AUTOSAR XML (schema 4-0-3)
package /EthernetSimple_Generic/Services/BswM
  impl type ComMModeEnum: compu {0=COMM_NO_COMMUNICATION, 1=COMM_SILENT_COMMUNICATION, 2=COMM_FULL_COMMUNICATION}, implementation-data-type=uint8
  sender receiver interface ComMModeRequestInterface
    data requestedMode: type=ComMModeEnum
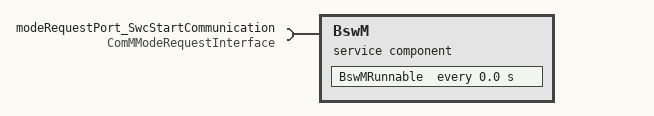
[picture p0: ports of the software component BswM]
  service sw component type BswM
    require port modeRequestPort_SwcStartCommunication: required-interface=ComMModeRequestInterface
    behavior BswMInternalBehavior: handle-termination-and-restart=NO-SUPPORT
      timing event BswMRunnableEvent: start-on-event=BswMRunnable, period=0.0
      runnable BswMRunnable: symbol=BswM_MainFunction
        data-receive-point-by-arguments:
          access dataReceivePoint_BswMRunnable_modeRequestPort_SwcStartCommunication_requestedMode: accessed-variable=modeRequestPort_SwcStartCommunication.requestedMode
  swc implementation BswMComponentImpl: programming-language=C, vendor-id=60, behavior=BswMInternalBehavior
    code-descriptors:
      code src: artifact-descriptors=autosar-engineering-object={short-label=artifactDescriptor, category=artifactDescriptorCategory}
    resource consumption resourceConsumption
package /EthernetSimple_Generic/Services/Os
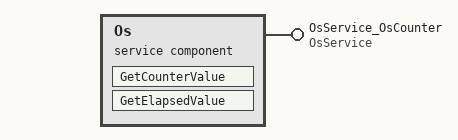
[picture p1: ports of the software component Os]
  service sw component type Os
    provide port OsService_OsCounter: provided-interface=OsService
    behavior OsBehavior: handle-termination-and-restart=NO-SUPPORT, port-api-option{port-defined-argument-value{value=CounterType:0, value-type=CounterType}, port=OsService_OsCounter}
      operation invoked event GetCounterValue_OsService_OsCounter_GetCounterValue: start-on-event=GetCounterValue, operation=OsService_OsCounter.GetCounterValue
      operation invoked event GetElapsedValue_OsService_OsCounter_GetElapsedValue: start-on-event=GetElapsedValue, operation=OsService_OsCounter.GetElapsedValue
      runnable GetCounterValue: symbol=Os_GetCounterValue
      runnable GetElapsedValue: symbol=Os_GetElapsedValue
  swc implementation OsImpl: programming-language=C, vendor-id=60, behavior=OsBehavior
    code-descriptors:
      code src: artifact-descriptors=autosar-engineering-object={short-label=artifactDescriptor, category=artifactDescriptorCategory}
    resource consumption resourceConsumption
package /EthernetSimple_Generic/Services/Det
  service sw component type Det
    behavior DetBehavior: handle-termination-and-restart=NO-SUPPORT
      runnable ReportError: symbol=Det_ReportError
  swc implementation DetImpl: programming-language=C, vendor-id=60, behavior=DetBehavior
    code-descriptors:
      code src: artifact-descriptors=autosar-engineering-object={short-label=artifactDescriptor, category=artifactDescriptorCategory}
    resource consumption resourceConsumption
package /EthernetSimple_Generic/Services/ComM
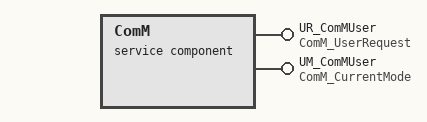
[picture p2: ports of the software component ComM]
  service sw component type ComM
    provide port UR_ComMUser: provided-interface=ComM_UserRequest
    provide port UM_ComMUser: provided-interface=ComM_CurrentMode
    behavior ComMBehavior: data-type-mapping=ComMTypeMappings, handle-termination-and-restart=NO-SUPPORT, port-api-option{port-defined-argument-value{value=ComM_UserHandleType:0, value-type=ComM_UserHandleType}, port=UR_ComMUser}
      4 x operation invoked event:
        RequestComMode_UR_ComMUser_RequestComMode: start-on-event=RequestComMode, operation=UR_ComMUser.RequestComMode
        GetMaxComMode_UR_ComMUser_GetMaxComMode: start-on-event=GetMaxComMode, operation=UR_ComMUser.GetMaxComMode
        GetRequestedComMode_UR_ComMUser_GetRequestedComMode: start-on-event=GetRequestedComMode, operation=UR_ComMUser.GetRequestedComMode
        GetCurrentComMode_UR_ComMUser_GetCurrentComMode: start-on-event=GetCurrentComMode, operation=UR_ComMUser.GetCurrentComMode
      5 x runnable:
        ComM_MainFunction
          mode switch point modeSwitchPoint_ComM_MainFunction_UM_ComMUser_currentMode: mode-group=UM_ComMUser.currentMode
        RequestComMode: can-be-invoked-concurrently=true, symbol=ComM_RequestComMode
        GetMaxComMode: can-be-invoked-concurrently=true, symbol=ComM_GetMaxComMode
        GetRequestedComMode: can-be-invoked-concurrently=true, symbol=ComM_GetRequestedComMode
        GetCurrentComMode: can-be-invoked-concurrently=true, symbol=ComM_GetCurrentComMode
  swc implementation ComMImpl: programming-language=C, vendor-id=60, behavior=ComMBehavior
    code-descriptors:
      code src: artifact-descriptors=autosar-engineering-object={short-label=artifactDescriptor, category=artifactDescriptorCategory}
    resource consumption resourceConsumption
package /EthernetSimple_Generic/Services/Dlt
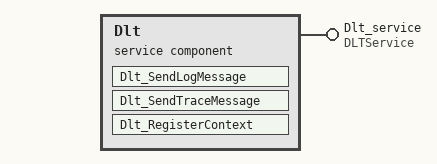
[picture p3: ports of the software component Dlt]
  service sw component type Dlt
    provide port Dlt_service: provided-interface=DLTService
    behavior DltBehavior: handle-termination-and-restart=NO-SUPPORT, port-api-option{port-defined-argument-value{value=Dlt_SessionIDType:4096, value-type=Dlt_SessionIDType}, port=Dlt_service}
      operation invoked event Dlt_SendLogMessage_Dlt_service_SendLogMessage: start-on-event=Dlt_SendLogMessage, operation=Dlt_service.SendLogMessage
      operation invoked event Dlt_SendTraceMessage_Dlt_service_SendTraceMessage: start-on-event=Dlt_SendTraceMessage, operation=Dlt_service.SendTraceMessage
      operation invoked event Dlt_RegisterContext_Dlt_service_RegisterContext: start-on-event=Dlt_RegisterContext, operation=Dlt_service.RegisterContext
      runnable Dlt_SendLogMessage
      runnable Dlt_SendTraceMessage
      runnable Dlt_RegisterContext
  swc implementation DltImpl: programming-language=C, vendor-id=60, behavior=DltBehavior
    code-descriptors:
      code src: artifact-descriptors=autosar-engineering-object={short-label=artifactDescriptor, category=artifactDescriptorCategory}
    resource consumption resourceConsumption
package /EthernetSimple_mpc5748g_mpc574xg_mb_Ecu/Services/EcuM
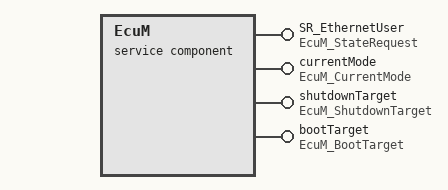
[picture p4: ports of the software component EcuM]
  service sw component type EcuM
    4 x provide port:
      SR_EthernetUser: provided-interface=EcuM_StateRequest
      currentMode: provided-interface=EcuM_CurrentMode
      shutdownTarget: provided-interface=EcuM_ShutdownTarget
      bootTarget: provided-interface=EcuM_BootTarget
    behavior EcuMFixedBehavior: data-type-mapping=EcuMFixedTypeMappings, handle-termination-and-restart=NO-SUPPORT, port-api-option{port-defined-argument-value{value=EcuM_UserType:0, value-type=EcuM_UserType}, port=SR_EthernetUser}
      9 x operation invoked event:
        RequestRUN_SR_EthernetUser_RequestRUN: start-on-event=RequestRUN, operation=SR_EthernetUser.RequestRUN
        ReleaseRUN_SR_EthernetUser_ReleaseRUN: start-on-event=ReleaseRUN, operation=SR_EthernetUser.ReleaseRUN
        RequestPOSTRUN_SR_EthernetUser_RequestPOSTRUN: start-on-event=RequestPOSTRUN, operation=SR_EthernetUser.RequestPOSTRUN
        ReleasePOSTRUN_SR_EthernetUser_ReleasePOSTRUN: start-on-event=ReleasePOSTRUN, operation=SR_EthernetUser.ReleasePOSTRUN
        SelectShutdownTarget_shutdownTarget_SelectShutdownTarget: start-on-event=SelectShutdownTarget, operation=shutdownTarget.SelectShutdownTarget
        GetShutdownTarget_shutdownTarget_GetShutdownTarget: start-on-event=GetShutdownTarget, operation=shutdownTarget.GetShutdownTarget
        GetLastShutdownTarget_shutdownTarget_GetLastShutdownTarget: start-on-event=GetLastShutdownTarget, operation=shutdownTarget.GetLastShutdownTarget
        SelectBootTarget_bootTarget_SelectBootTarget: start-on-event=SelectBootTarget, operation=bootTarget.SelectBootTarget
        GetBootTarget_bootTarget_GetBootTarget: start-on-event=GetBootTarget, operation=bootTarget.GetBootTarget
      10 x runnable:
        EcuM_MainFunction
          mode switch point modeSwitchPoint_EcuM_MainFunction_currentMode_currentMode: mode-group=currentMode.currentMode
        RequestRUN: can-be-invoked-concurrently=true, symbol=EcuM_RequestRUN
        ReleaseRUN: can-be-invoked-concurrently=true, symbol=EcuM_ReleaseRUN
        RequestPOSTRUN: can-be-invoked-concurrently=true, symbol=EcuM_RequestPOST_RUN
        ReleasePOSTRUN: can-be-invoked-concurrently=true, symbol=EcuM_ReleasePOST_RUN
        SelectShutdownTarget: can-be-invoked-concurrently=true, symbol=EcuM_SelectShutdownTarget
        GetShutdownTarget: can-be-invoked-concurrently=true, symbol=EcuM_GetShutdownTarget
        GetLastShutdownTarget: can-be-invoked-concurrently=true, symbol=EcuM_GetLastShutdownTarget
        SelectBootTarget: can-be-invoked-concurrently=true, symbol=EcuM_SelectBootTarget
        GetBootTarget: can-be-invoked-concurrently=true, symbol=EcuM_GetBootTarget
  swc implementation EcuMFixedImpl: programming-language=C, vendor-id=60, behavior=EcuMFixedBehavior
    code-descriptors:
      code src: artifact-descriptors=autosar-engineering-object={short-label=artifactDescriptor, category=artifactDescriptorCategory}
    resource consumption resourceConsumption
package /EthernetSimple_mpc5748g_mpc574xg_mb_Ecu/Services/IoHwAb
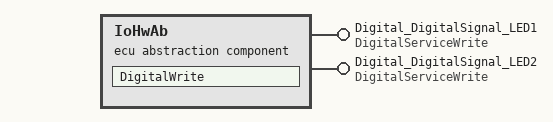
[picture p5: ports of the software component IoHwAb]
  ecu abstraction sw component type IoHwAb
    provide port Digital_DigitalSignal_LED1: provided-interface=DigitalServiceWrite
    provide port Digital_DigitalSignal_LED2: provided-interface=DigitalServiceWrite
    behavior IoHwAbBehavior: handle-termination-and-restart=NO-SUPPORT
      operation invoked event DigitalWrite_Digital_DigitalSignal_LED1_Write: start-on-event=DigitalWrite, operation=Digital_DigitalSignal_LED1.Write
      operation invoked event DigitalWrite_Digital_DigitalSignal_LED2_Write: start-on-event=DigitalWrite, operation=Digital_DigitalSignal_LED2.Write
      port-api-options:
        {port-defined-argument-value{value=IoHwAb_SignalType_:0, value-type=IoHwAb_SignalType_}, port=Digital_DigitalSignal_LED1}
        {port-defined-argument-value{value=IoHwAb_SignalType_:1, value-type=IoHwAb_SignalType_}, port=Digital_DigitalSignal_LED2}
      runnable DigitalWrite: can-be-invoked-concurrently=true, symbol=IoHwAb_Digital_Write
  swc implementation IoHwAbImpl: programming-language=C, vendor-id=60, behavior=IoHwAbBehavior
    code-descriptors:
      code src: artifact-descriptors=autosar-engineering-object={short-label=artifactDescriptor, category=artifactDescriptorCategory}
    resource consumption resourceConsumption
package /EthernetSimple
  system EthernetSimple: category=ECU_EXTRACT, system-version=1
    system mapping ImplementationMappings
      sw-impl-mappings:
        7 x swc to impl mapping:
          comMMapping: component-implementation=ComMImpl, component=RootSwComposition.comM
          dltMapping: component-implementation=DltImpl, component=RootSwComposition.dlt
          bswMMapping: component-implementation=BswMComponentImpl, component=RootSwComposition.bswm
          ecuMMapping: component-implementation=EcuMFixedImpl, component=RootSwComposition.ecuM
          ioHwAbMapping: component-implementation=IoHwAbImpl, component=RootSwComposition.ioHwAb
          SwcReaderMapping: component-implementation=SwcReaderImpl, component=RootSwComposition.SwcReader
          SwcWriterMapping: component-implementation=SwcWriterImpl, component=RootSwComposition.SwcWriter
    system mapping SignalMappings
      data-mappings:
        data-element=RootSwComposition.Tx01.data2, system-signal=Tx01dataSSig
        data-element=RootSwComposition.Rx01.data1, system-signal=Rx01dataSSig
    root-software-compositions:
      root sw composition prototype RootSwComposition: software-composition=TopLevelComposition
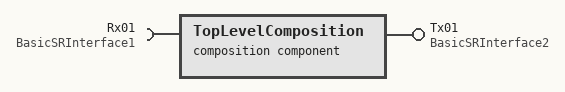
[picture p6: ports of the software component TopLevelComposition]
  composition sw component type TopLevelComposition
    provide port Tx01: provided-interface=BasicSRInterface2
    require port Rx01: required-interface=BasicSRInterface1
    7 x component:
      SwcReader: type=SwcReaderType
      SwcWriter: type=SwcWriterType
      ecuM: type=EcuM
      ioHwAb: type=IoHwAb
      comM: type=ComM
      dlt: type=Dlt
      bswm: type=BswM
    connect ioHwAb.Digital_DigitalSignal_LED1 -> SwcReader.Blinker
    connect ioHwAb.Digital_DigitalSignal_LED2 -> SwcWriter.Blinker
    connect ecuM.SR_EthernetUser -> SwcReader.RunControl
    connect ecuM.currentMode -> SwcReader.Mode
    connect ecuM.currentMode -> SwcWriter.Mode
    connect SwcReader.ResultPort -> SwcWriter.InputPort
    connect SwcWriter.ComMControl -> bswm.modeRequestPort_SwcStartCommunication
    connect dlt.Dlt_service -> SwcReader.Dlt
    delegate SwcWriter.SenderPort <-> outer port Tx01
    delegate SwcReader.ReceiverPort <-> outer port Rx01
package /EthernetSimple/Communication
  pdu Rx01dataIPdu: unused-bit-pattern=0
    signal Rx01dataISig: 0 bit, system signal Rx01dataSSig, data-type-policy=NETWORK-REPRESENTATION-FROM-COM-SPEC
  pdu Tx01dataIPdu: unused-bit-pattern=0
    signal Tx01dataISig: 0 bit, system signal Tx01dataSSig, data-type-policy=NETWORK-REPRESENTATION-FROM-COM-SPEC
package /Interfaces
  sender receiver interface BasicSRInterface1
    data data1: type=uint32
  sender receiver interface BasicSRInterface2
    data data2: type=sint32
package /SwcReader
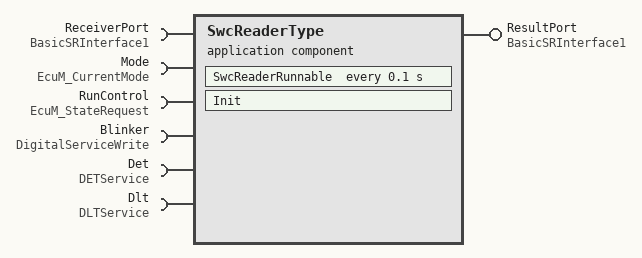
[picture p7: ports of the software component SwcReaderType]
  application sw component type SwcReaderType
    require port ReceiverPort: required-interface=BasicSRInterface1
    provide port ResultPort: provided-interface=BasicSRInterface1
    5 x require port:
      Mode: required-interface=EcuM_CurrentMode
      RunControl: required-interface=EcuM_StateRequest
      Blinker: required-interface=DigitalServiceWrite
      Det: required-interface=DETService
      Dlt: required-interface=DLTService
    behavior SwcReaderBehavior: data-type-mapping=EcuMFixedTypeMappings, handle-termination-and-restart=NO-SUPPORT
      timing event SwcReaderRunnable_timingEvent_0_1: start-on-event=SwcReaderRunnable, period=0.1
      swc mode switch event InitEvent: start-on-event=SwcReaderBehavior/Init, activation=ON-EXIT, mode=Mode.currentMode.STARTUP
      runnable SwcReaderRunnable: symbol=swcReaderRunnable
        data-read-access:
          access dataReadAccess_SwcReaderRunnable_ReceiverPort_data1: accessed-variable=ReceiverPort.data1
        data-write-access:
          access dataWriteAccess_SwcReaderRunnable_ResultPort_data1: accessed-variable=ResultPort.data1
        sync call Blinker1CallPoint: operation=Blinker.Write, timeout=0.0
        sync call Det_ReportError: operation=Det.ReportError, timeout=0.0
        sync call Dlt_SendLogMessage: operation=Dlt.SendLogMessage, timeout=0.0
      runnable Init: symbol=swcReaderInit
        sync call RunControl_RequestRUN: operation=RunControl.RequestRUN, timeout=0.0
  swc implementation SwcReaderImpl: programming-language=C, vendor-id=0, behavior=SwcReaderBehavior
    code-descriptors:
      code src: artifact-descriptors=autosar-engineering-object={short-label=artifactDescriptor, category=artifactDescriptorCategory}
    resource consumption resourceConsumption
package /SwcWriter
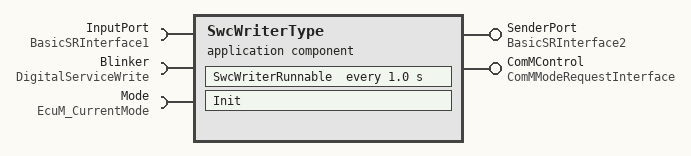
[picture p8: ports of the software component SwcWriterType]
  application sw component type SwcWriterType
    require port InputPort: required-interface=BasicSRInterface1
    provide port SenderPort: provided-interface=BasicSRInterface2
    require port Blinker: required-interface=DigitalServiceWrite
    provide port ComMControl: provided-interface=ComMModeRequestInterface
    require port Mode: required-interface=EcuM_CurrentMode
    behavior SwcWriterBehavior: data-type-mapping=EcuMFixedTypeMappings, handle-termination-and-restart=NO-SUPPORT
      timing event SwcWriterRunnable_timingEvent_1_0: start-on-event=SwcWriterRunnable, period=1.0
      swc mode switch event InitEvent: start-on-event=SwcWriterBehavior/Init, activation=ON-EXIT, mode=Mode.currentMode.STARTUP
      runnable SwcWriterRunnable: symbol=swcWriterRunnable
        data-read-access:
          access dataReadAccess_SwcWriterRunnable_InputPort_data1: accessed-variable=InputPort.data1
        data-write-access:
          access dataWriteAccess_SwcWriterRunnable_SenderPort_data2: accessed-variable=SenderPort.data2
        sync call Blinker2CallPoint: operation=Blinker.Write, timeout=0.0
      runnable Init: symbol=SwcWriterInit
        data-write-access:
          access dataWriteAccess_Init_ComMControl_requestedMode: accessed-variable=ComMControl.requestedMode
  swc implementation SwcWriterImpl: programming-language=C, vendor-id=0, behavior=SwcWriterBehavior
    code-descriptors:
      code src: artifact-descriptors=autosar-engineering-object={short-label=artifactDescriptor, category=artifactDescriptorCategory}
    resource consumption resourceConsumption
